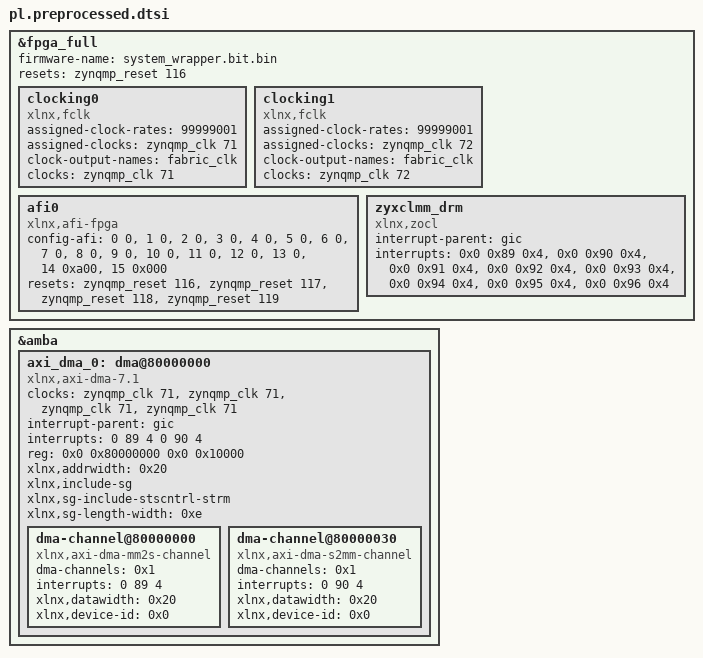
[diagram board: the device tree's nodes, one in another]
# 0 "./dts_output/pl.dtsi"
# 0 "<built-in>"
# 0 "<command-line>"
# 1 "./dts_output/pl.dtsi"







/dts-v1/;
/plugin/;
&fpga_full {
 firmware-name = "system_wrapper.bit.bin";
 resets = <&zynqmp_reset 116>;
 clocking0: clocking0 {
  #clock-cells = <0>;
  assigned-clock-rates = <99999001>;
  assigned-clocks = <&zynqmp_clk 71>;
  clock-output-names = "fabric_clk";
  clocks = <&zynqmp_clk 71>;
  compatible = "xlnx,fclk";
 };
 clocking1: clocking1 {
  #clock-cells = <0>;
  assigned-clock-rates = <99999001>;
  assigned-clocks = <&zynqmp_clk 72>;
  clock-output-names = "fabric_clk";
  clocks = <&zynqmp_clk 72>;
  compatible = "xlnx,fclk";
 };
 afi0: afi0 {
  compatible = "xlnx,afi-fpga";
  config-afi = < 0 0>, <1 0>, <2 0>, <3 0>, <4 0>, <5 0>, <6 0>, <7 0>, <8 0>, <9 0>, <10 0>, <11 0>, <12 0>, <13 0>, <14 0xa00>, <15 0x000>;
  resets = <&zynqmp_reset 116>, <&zynqmp_reset 117>, <&zynqmp_reset 118>, <&zynqmp_reset 119>;
 };
 zyxclmm_drm {
  compatible = "xlnx,zocl";
  interrupt-parent = <&gic>;
  interrupts = <0x0 0x89 0x4>, <0x0 0x90 0x4>, <0x0 0x91 0x4>, <0x0 0x92 0x4>, <0x0 0x93 0x4>, <0x0 0x94 0x4>, <0x0 0x95 0x4>, <0x0 0x96 0x4>;
 };
};
&amba {
 #address-cells = <2>;
 #size-cells = <2>;
 axi_dma_0: dma@80000000 {
  #dma-cells = <1>;
  clock-names = "m_axi_mm2s_aclk", "m_axi_s2mm_aclk", "m_axi_sg_aclk", "s_axi_lite_aclk";
  clocks = <&zynqmp_clk 71>, <&zynqmp_clk 71>, <&zynqmp_clk 71>, <&zynqmp_clk 71>;
  compatible = "xlnx,axi-dma-7.1", "xlnx,axi-dma-1.00.a";
  interrupt-names = "mm2s_introut", "s2mm_introut";
  interrupt-parent = <&gic>;
  interrupts = <0 89 4 0 90 4>;
  reg = <0x0 0x80000000 0x0 0x10000>;
  xlnx,addrwidth = <0x20>;
  xlnx,include-sg ;
  xlnx,sg-include-stscntrl-strm ;
  xlnx,sg-length-width = <0xe>;
  dma-channel@80000000 {
   compatible = "xlnx,axi-dma-mm2s-channel";
   dma-channels = <0x1>;
   interrupts = <0 89 4>;
   xlnx,datawidth = <0x20>;
   xlnx,device-id = <0x0>;
  };
  dma-channel@80000030 {
   compatible = "xlnx,axi-dma-s2mm-channel";
   dma-channels = <0x1>;
   interrupts = <0 90 4>;
   xlnx,datawidth = <0x20>;
   xlnx,device-id = <0x0>;
  };
 };
};
